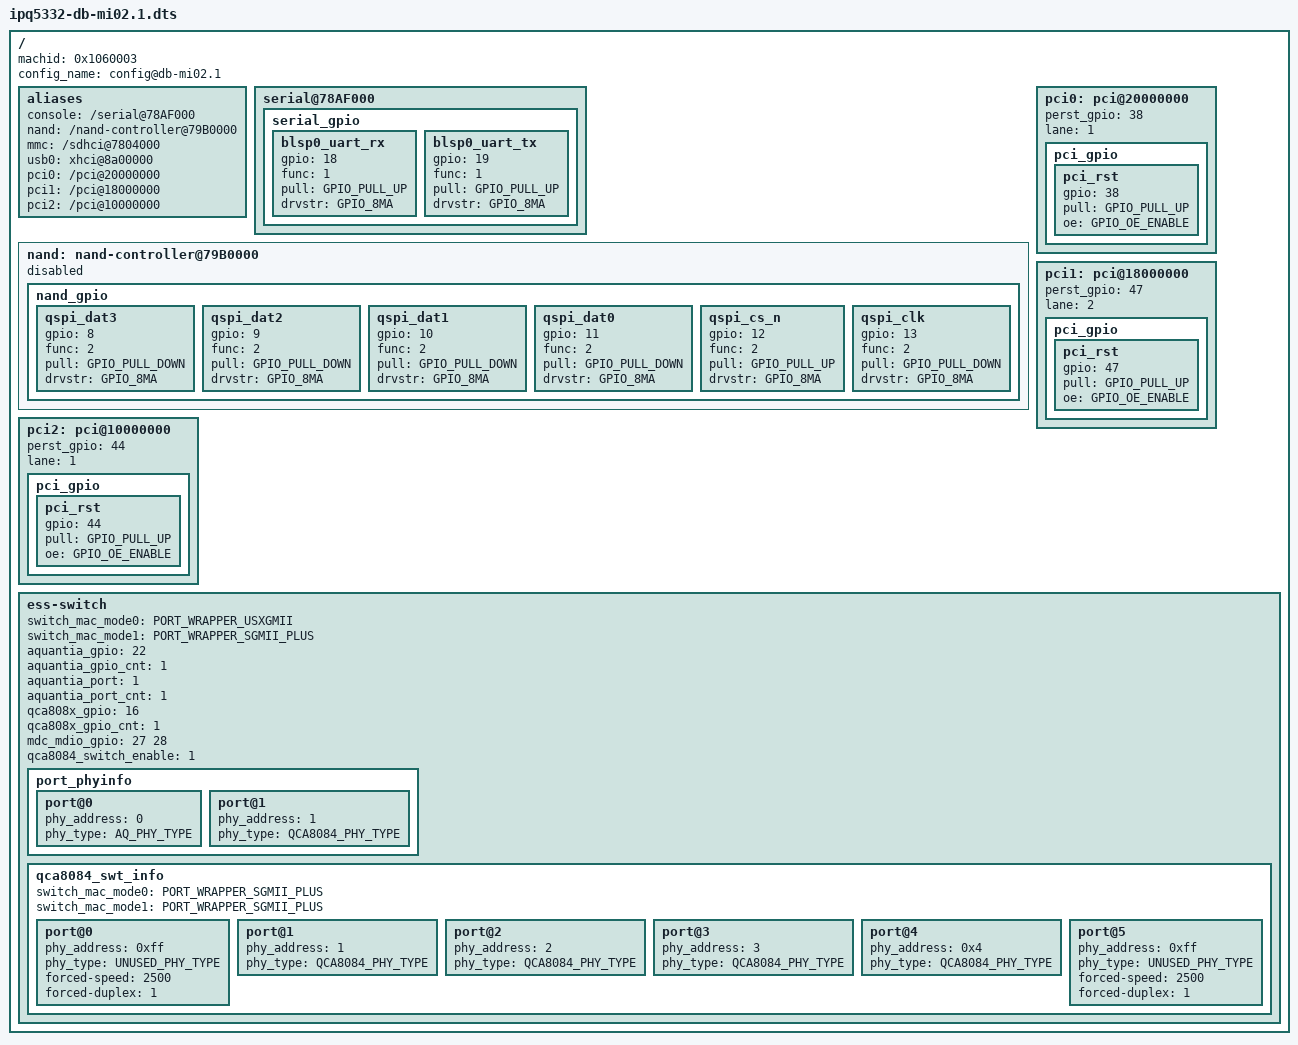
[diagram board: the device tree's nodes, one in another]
/*
 * Copyright (c) 2016-2021, The Linux Foundation. All rights reserved.
 *
 * Copyright (c) 2022 Qualcomm Innovation Center, Inc. All rights reserved.
 *
 * This program is free software; you can redistribute it and/or modify
 * it under the terms of the GNU General Public License version 2 and
 * only version 2 as published by the Free Software Foundation.
 *
 * This program is distributed in the hope that it will be useful,
 * but WITHOUT ANY WARRANTY; without even the implied warranty of
 * MERCHANTABILITY or FITNESS FOR A PARTICULAR PURPOSE.  See the
 * GNU General Public License for more details.
 */

/dts-v1/;
#include "ipq5332-soc.dtsi"
/ {
	machid = <0x1060003>;
	config_name = "config@db-mi02.1";

	aliases {
		console = "/serial@78AF000";
		nand = "/nand-controller@79B0000";
		mmc = "/sdhci@7804000";
		usb0 = "xhci@8a00000";
		pci0 = "/pci@20000000";
		pci1 = "/pci@18000000";
		pci2 = "/pci@10000000";
	};

	serial@78AF000 {
		status = "ok";
		serial_gpio {
			blsp0_uart_rx {
				gpio = <18>;
				func = <1>;
				pull = <GPIO_PULL_UP>;
				drvstr = <GPIO_8MA>;
			};
			blsp0_uart_tx {
				gpio = <19>;
				func = <1>;
				pull = <GPIO_PULL_UP>;
				drvstr = <GPIO_8MA>;
			};
		};
	};

	nand: nand-controller@79B0000 {
		status = "disabled";
		nand_gpio {
			qspi_dat3 {
				gpio = <8>;
				func = <2>;
				pull = <GPIO_PULL_DOWN>;
				drvstr = <GPIO_8MA>;
			};
			qspi_dat2 {
				gpio = <9>;
				func = <2>;
				pull = <GPIO_PULL_DOWN>;
				drvstr = <GPIO_8MA>;
			};
			qspi_dat1 {
				gpio = <10>;
				func = <2>;
				pull = <GPIO_PULL_DOWN>;
				drvstr = <GPIO_8MA>;
			};
			qspi_dat0 {
				gpio = <11>;
				func = <2>;
				pull = <GPIO_PULL_DOWN>;
				drvstr = <GPIO_8MA>;
			};
			qspi_cs_n {
				gpio = <12>;
				func = <2>;
				pull = <GPIO_PULL_UP>;
				drvstr = <GPIO_8MA>;
			};
			qspi_clk {
				gpio = <13>;
				func = <2>;
				pull = <GPIO_PULL_DOWN>;
				drvstr = <GPIO_8MA>;
			};
		};
	};

	pci0: pci@20000000 {
		status = "ok";
		perst_gpio = <38>;
		lane = <1>;
		pci_gpio {
			pci_rst {
				gpio = <38>;
				pull = <GPIO_PULL_UP>;
				oe = <GPIO_OE_ENABLE>;
			};
		};
	};

	pci1: pci@18000000 {
		status = "ok";
		perst_gpio = <47>;
		lane = <2>;
		pci_gpio {
			pci_rst {
				gpio = <47>;
				pull = <GPIO_PULL_UP>;
				oe = <GPIO_OE_ENABLE>;
			};
		};
	};

	pci2: pci@10000000 {
		status = "ok";
		perst_gpio = <44>;
		lane = <1>;
		pci_gpio {
			pci_rst {
				gpio = <44>;
				pull = <GPIO_PULL_UP>;
				oe = <GPIO_OE_ENABLE>;
			};
		};
	};

	ess-switch {
		switch_mac_mode0 = <PORT_WRAPPER_USXGMII>;
		switch_mac_mode1 = <PORT_WRAPPER_SGMII_PLUS>;
		aquantia_gpio = <22>;
		aquantia_gpio_cnt = <1>;
		aquantia_port = <1>;
		aquantia_port_cnt = <1>;
		qca808x_gpio = <16>;
		qca808x_gpio_cnt = <1>;
		mdc_mdio_gpio = <27 28>;

		qca8084_switch_enable = <1>;

		port_phyinfo {
			port@0 {
				phy_address = <0>;
				phy_type = <AQ_PHY_TYPE>;
			};
			port@1 {
				phy_address = <1>;
				phy_type = <QCA8084_PHY_TYPE>;
			};
		};

		qca8084_swt_info {
			switch_mac_mode0 = <PORT_WRAPPER_SGMII_PLUS>;
			switch_mac_mode1 = <PORT_WRAPPER_SGMII_PLUS>;

			port@0 {
				phy_address = <0xff>;
				phy_type = <UNUSED_PHY_TYPE>;
				forced-speed = <2500>;
				forced-duplex = <1>;
			};
			port@1 {
				phy_address = <1>;
				phy_type = <QCA8084_PHY_TYPE>;
			};
			port@2 {
				phy_address = <2>;
				phy_type = <QCA8084_PHY_TYPE>;
			};
			port@3 {
				phy_address = <3>;
				phy_type = <QCA8084_PHY_TYPE>;
			};
			port@4 {
				phy_address = <0x4>;
				phy_type = <QCA8084_PHY_TYPE>;
			};
			port@5 {
				phy_address = <0xff>;
				phy_type = <UNUSED_PHY_TYPE>;
				forced-speed = <2500>;
				forced-duplex = <1>;
			};
		};
	};
};
